# TC37XPD register map
Vendor: Infineon; Series: ATVMC; File version: 100
CPU: other r0p0, little endian, MPU, FPU, vendor SysTick, 4 interrupt priority bits
Registers are 32-bit, read-write, reset 0x0 unless marked. A register's access mark holds for its fields unless they carry their own. Offsets are from the block's base; [hi:lo] are bit positions; lines under a group give offsets from that group; {n}, {i} and the like mark numbered series; 'fields as' and 'values as' point back to an identical list.

## DMU
Base 0xF8040000
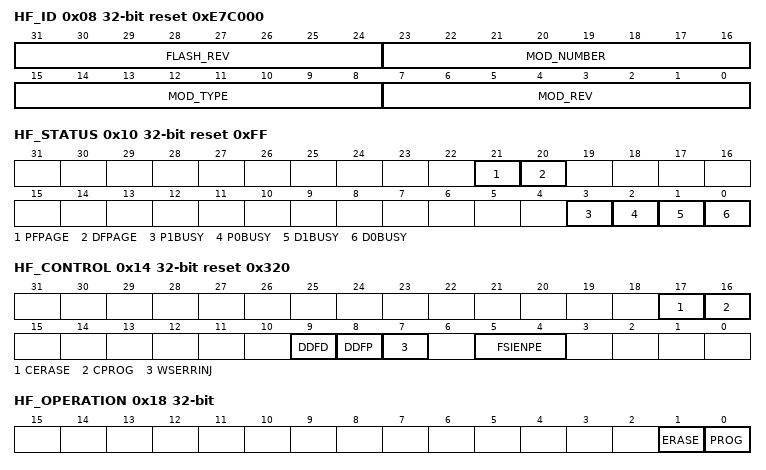
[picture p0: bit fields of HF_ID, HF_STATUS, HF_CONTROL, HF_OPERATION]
0x08 HF_ID ro reset 0xE7C000 (reset mask 0xFFFF00) — Module Identification Register resetvalue={Application Reset:0x0E7C000}
  [31:24] FLASH_REV — Flash Revision FLASH REV. This bit field defines the flash revision number. 31 28 identifies the product. For example 0x9h indicates TC39x product 0x8h indicates TC38x product etc. 27 24 identifies the product revision.
  [23:16] MOD_NUMBER — Module Number Value MOD NUMBER. This bit field defines the module identification number.
  [15:8] MOD_TYPE — Module Type MOD TYPE. The bit field is set to C0 which defines the module as a 32 bit module.
  [7:0] MOD_REV — Module Revision Number MOD REV. This bit field defines the module revision number reflecting major changes in the module.
0x10 HF_STATUS ro reset 0xFF — Flash Status Register resetvalue={Application Reset:0x0FF}
  [21] PFPAGE — Program Flash in Page Mode PFPAGE. HW controlled status flag. Set with Enter Page Mode for Flash cleared with Write Page command This bit is not set by 8220 Enter Page Mode 8221 initiated by the HSM interface. Read accesses are allowed while in page mode.
  [20] DFPAGE — Data Flash in Page Mode DFPAGE. HW controlled status flag. Set with Enter Page Mode for DFLASH cleared with Write Page command. This bit is not set by 8220 Enter Page Mode 8221 initiated by the HSM interface. Read accesses are allowed while in page mode.
  [3] P1BUSY — Program Flash PF5BUSY P5BUSY. HW controlled status flag. Indication of busy state of PFx because of active execution of an operation PFx busy state is also indicated during Flash startup after reset or in sleep mode while in busy state the PFx does not allow read access.
  [2] P0BUSY — Program Flash PF5BUSY P5BUSY. HW controlled status flag. Indication of busy state of PFx because of active execution of an operation PFx busy state is also indicated during Flash startup after reset or in sleep mode while in busy state the PFx does not allow read access.
  [1] D1BUSY — Data Flash Bank 1 Busy D1BUSY. HW controlled status flag. Indication of busy state of DFLASH bank 160 1 because of active execution of an operation DF1 busy state is also indicated during Flash startup after reset or in sleep mode while in busy state the DF1 does not allow read access. Bit is not set for program erase operations initiated by the HSM interface.
  [0] D0BUSY — Data Flash Bank 0 Busy D0BUSY. HW controlled status flag. Indication of busy state of DFLASH bank 160 0 because of active execution of an operation DF0 busy state is also indicated during Flash startup after reset or in sleep mode while in busy state the DF0 does not allow read access.
0x14 HF_CONTROL access per field reset 0x320 — Flash Control Register resetvalue={Application Reset:0x320}
  [17] CERASE wo — Clear Erase State CERASE
  [16] CPROG wo — Clear Programming State CPROG
  [9] DDFD rw — Disable Data Fetch from DF0 EEPROM DDFD. This bit enables disables the data fetch from DF0 EEPROM. DMU ramp up and SSW start up This bit is automatically set with reset and is cleared during startup if no Read Protection installed and during startup BROM SW in case of internal start out of Flash. This is realized by allowing full write access with inactive startup protection. User Software Clearing DF0 EEPROM Read Protection Once set DMU HF CONTROL .DDFD can only be cleared when DMU HF PROTECT .PRODISD or not DMU HF PROCONDF .RPRO User Software Setting DF0 EEPROM Read Protection Software must write DMU HF CONTROL .DDFD to 1
  [8] DDFP rw — Disable Read from PFLASH DDFP. This bit enables disables the read access to PFLASH. DMU ramp up and SSW start up This bit is automatically set with reset and is cleared during startup if no Read Protection installed and during startup SSW in case of internal start out of Flash. This is realized by allowing full write access with inactive startup protection. User Software Clearing PFLASH Read Protection Once set DMU HF CONTROL .DDFP can only be cleared when DMU HF PROTECT .PRODISP or DMU HF PROTECT .PRODISP0 5 or not DMU HF PROCONPF .RPRO User Software Setting PFLASH Read Protection Software must write DMU HF CONTROL .DDFP to 1
  [7] WSERRINJ rw — PFlash Wait State ECC error injection WSERRINJ. Error injection into the ECC logic protecting PFlash Wait states.
  [5:4] FSIENPE rw — Enable Program Erase FSIENPE. The field prevents any Flash program or erase directly in the FSI. It is set to 8220 Enabled 8221 by the SSW upon finishing the startup. Once in the 8220 enabled 8221 state this field cannot be changed.
    0=Disabled0 (00 Disabled Program Erase are disabled in the FSI.); 1=Enabled1 (01 Enabled Program Erase are enabled in the FSI.); 2=Disabled2 (10 Disabled Program Erase are disabled in the FSI.); 3=Disabled3 (11 Disabled Program Erase are disabled in the FSI.)
0x18 HF_OPERATION ro — Flash Operation Register resetvalue={System Reset:0x0}
  [1] ERASE — Erase State ERASE. HW controlled status flag. Set with last cycle of Erase Verify command sequence. Indications are analogous to PROG flag. May be cleared by writing 1 to DMU HF CONTROL .CERASE. This bit is not set for by erase operations initiated by the HSM interface. Cleared with command Clear Status .
  [0] PROG — Programming State PROG. HW controlled status flag. Set with last cycle of Write Page Burst and Replace Logical Sector command sequences. If one BUSY flag is coincidently set PROG indicates the type of busy state. If OPER is coincidently set PROG indicates the type of erroneous operation. Otherwise PROG indicates that operation is still requested or finished. May be also cleared by writing 8216 1 8217 to DMU HF CONTROL .CPROG. This bit is not set for by program operations initiated by the HSM interface. Cleared with command 8220 Clear Status 8221 .
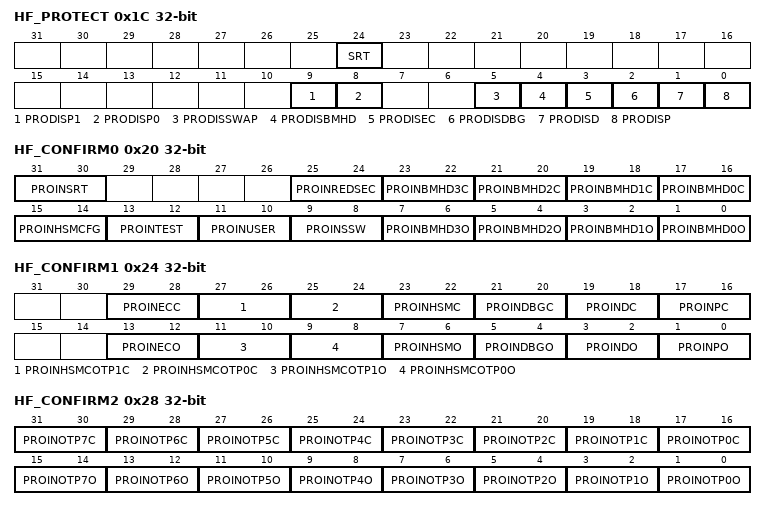
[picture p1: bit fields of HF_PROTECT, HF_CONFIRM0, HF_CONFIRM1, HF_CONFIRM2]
0x1C HF_PROTECT ro — Flash Protection Status Register resetvalue={Application Reset:0x0}
  [24] SRT — Secure Retest Password Protection Disabled SRT. Cleared with command Resume Protection .
  [9] PRODISP1 — Program Flash Protection Disable PRODISP5. The protection configured for PFx by UCB PFLASH ORIG and UCB PFLASH COPY was successfully disabled by supplying the correct password to 8220 Disable Protection 8221 . Cleared with command quot Resume Protection quot .
  [8] PRODISP0 — Program Flash Protection Disable PRODISP5. The protection configured for PFx by UCB PFLASH ORIG and UCB PFLASH COPY was successfully disabled by supplying the correct password to 8220 Disable Protection 8221 . Cleared with command quot Resume Protection quot .
  [5] PRODISSWAP — UCB SWAP protection Disabled PRODISSWAP. The protection configured by UCB SWAP ORIG and UCB SWAP COPY was successfully disabled by supplying the correct password to 8220 Disable Protection 8221 . Cleared with command quot Resume Protection quot .
  [4] PRODISBMHD — BMHD Protection Disabled PRODISBMHD. The protection configured by UCB BMHD0 ORIG and UCB BMHD0 COPY was successfully disabled by supplying the correct password to 8220 Disable Protection 8221 . Cleared with command quot Resume Protection quot .
  [3] PRODISEC — Erase Counter Priority Protection Disabled PRODISEC. The protection configured by UCB ECPRIO ORIG and UCB ECPRIO COPY was successfully disabled by supplying the correct password to 8220 Disable Protection 8221 . Cleared with command quot Resume Protection quot .
  [2] PRODISDBG — Debug Interface Password Protection Disabled PRODISDBG. The password configured by UCB DBG ORIG and UCB DBG COPY was correctly received with 8220 Disable Protection 8221 . When DMU SP PROCONHSMCFG.DESTDBG is 8220 destructive 8221 then only the SSW can disable this protection. This means PRODISDBG is only set when the password matches and DESTDBG 8220 non destructive 8221 or SCU STCON.STP 0 . Cleared with command 8220 Resume Protection 8221 .
  [1] PRODISD — DFLASH Protection Disabled PRODISD. The protection configured by UCB DFLASH ORIG and UCB DFLASH COPY was successfully disabled by supplying the correct password to 8220 Disable Protection 8221 . Cleared with command 8220 Resume Protection 8221 .
  [0] PRODISP — PFLASH Protection Disabled PRODISP. The protection configured by UCB PFLASH ORIG and UCB PFLASH COPY was successfully disabled by supplying the correct password to 8220 Disable Protection 8221 . Cleared with command 8220 Resume Protection 8221 .
0x20 HF_CONFIRM0 ro — Flash Confirm Status Register 0 resetvalue={Application Reset:0x0}
  [31:30] PROINSRT — UCB RETEST Confirmation PROINSRT. This bit reflects the confirmed state of UCB RETEST.
  [25:24] PROINREDSEC — UCB REDSEC Confirmation PROINREDSEC. This bit reflects the confirmed state of UCB REDSEC
  [2n+17:2n+16] PROINBMHD{n}C (n=0..3) — UCB BMHD{n} COPY Confirmation PROINBMHD{n}C. This bit reflects the confirmed state of UCB BMHD{n} COPY.
  [15:14] PROINHSMCFG — UCB HSMCFG Confirmation PROINHSMCFG. This bit reflects the confirmed state of UCB HSMCFG.
  [13:12] PROINTEST — UCB TEST Confirmation PROINTEST. This bit reflects the confirmed state of UCB TEST.
  [11:10] PROINUSER — UCB USER Confirmation PROINUSER. This bit reflects the confirmed state of UCB USER.
  [9:8] PROINSSW — UCB SSW Confirmation PROINSSW. This bit reflects the confirmed state of UCB SSW.
  [2n+1:2n] PROINBMHD{n}O (n=0..3) — UCB BMHD{n} ORIG Confirmation PROINBMHD{n}O. This bit reflects the confirmed state of UCB BMHD{n} ORIG.
0x24 HF_CONFIRM1 ro — Flash Confirm Status Register 1 resetvalue={Application Reset:0x0}
  [29:28] PROINECC — UCB ECPRIO COPY Confirmation PROINECC. This bit reflects the confirmed state of UCB ECPRIO COPY
  [27:26] PROINHSMCOTP1C — UCB HSMCOTP1 COPY Protection PROINHSMCOTP1C. This bit reflects the confirmed state of UCB HSMCOTP1 COPY.
  [25:24] PROINHSMCOTP0C — UCB HSMCOTP0 COPY Protection PROINHSMCOTP0C. This bit reflects the confirmed state of UCB HSMCOTP0 COPY.
  [23:22] PROINHSMC — UCB HSM COPY Confirmation PROINHSMC. This bit reflects the confirmed state of UCB HSM COPY.
  [21:20] PROINDBGC — UCB DBG COPY Interface Confirmation PROINDBGC. This bit reflects the confirmed state of UCB DBG COPY.
  [19:18] PROINDC — UCB DFLASH COPY Confirmation PROINDC. This bit reflects the confirmed state of UCB DFLASH COPY.
  [17:16] PROINPC — UCB PFLASH COPY Confirmation PROINPC. This bit reflects the confirmed state of UCB PFLASH COPY.
  [13:12] PROINECO — UCB ECPRIO ORIG Confirmation PROINECO. This bit reflects the confirmed state of UCB ECPRIO ORIG.
  [11:10] PROINHSMCOTP1O — UCB HSMCOTP1 ORIG Protection PROINHSMCOTP1O. This bit reflects the confirmed state of UCB HSMCOTP1 ORIG.
  [9:8] PROINHSMCOTP0O — UCB HSMCOTP0 ORIG Protection PROINHSMCOTP0O. This bit reflects the confirmed state of UCB HSMCOTP0 ORIG.
  [7:6] PROINHSMO — UCB HSM ORIG Confirmation PROINHSMO. This bit reflects the confirmed state of UCB HSM ORIG.
  [5:4] PROINDBGO — UCB DBG ORIG Confirmation PROINDBGO. This bit reflects the confirmed state of UCB DBG ORIG.
  [3:2] PROINDO — UCB DFLASH ORIG Confirmation PROINDO. This bit reflects the confirmed state of UCB DFLASH ORIG.
  [1:0] PROINPO — UCB PFLASH ORIG Confirmation PROINPO. This bit reflects the confirmed state of UCB PFLASH ORIG.
0x28 HF_CONFIRM2 ro — Flash Confirm Status Register 2 resetvalue={Application Reset:0x0}
  [2n+17:2n+16] PROINOTP{n}C (n=0..7) — UCB OTP{n} COPY Confirmation PROINOTP{n}C. This bit reflects the confirmed state of UCB OTP{n} COPY.
  [2n+1:2n] PROINOTP{n}O (n=0..7) — UCB OTP{n} ORIG Confirmation PROINOTP{n}O. This bit reflects the confirmed state of UCB OTP{n} ORIG.
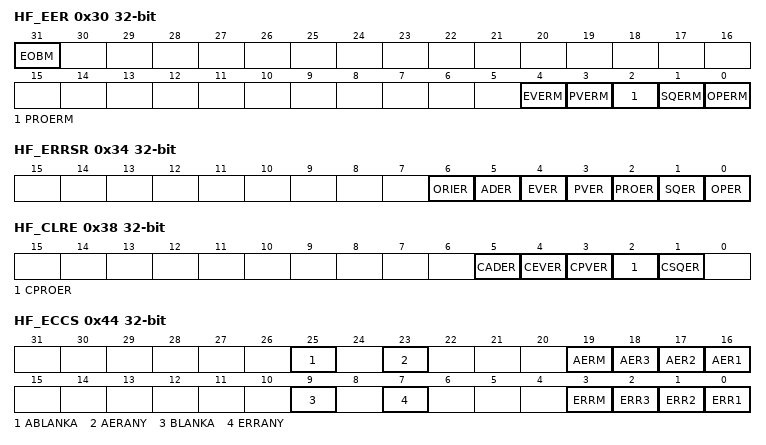
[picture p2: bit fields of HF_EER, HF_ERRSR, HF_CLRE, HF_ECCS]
0x30 HF_EER — Enable Error Interrupt Control Register resetvalue={Application Reset:0x0}
  [31] EOBM — End of Busy Interrupt Mask EOBM
  [4] EVERM — Erase Verify Error Interrupt Mask EVERM
  [3] PVERM — Program Verify Error Interrupt Mask PVERM
  [2] PROERM — Protection Error Interrupt Mask PROERM
  [1] SQERM — Command Sequence Error Interrupt Mask SQERM
  [0] OPERM — Operation Error Interrupt Mask OPERM
0x34 HF_ERRSR ro — Error Status Register resetvalue={Application Reset:0x0}
  [6] ORIER — Original Error ORIER. If a UCB contains both ORIG and COPY confirmation codes and during startup an ERRORED value or an uncorrectable ECC error is detected in the ORIG confirmation code then the original error flag is set by hardware. Cleared with application reset.
  [5] ADER — SRI Bus Address ECC Error ADER. This flag is set when the DMU detects an ECC error in the address phase bus transaction on the SRI bus. Cleared with application reset or writing DMU HF CLRE .CADER 1 .
  [4] EVER — Erase Verify Error EVER. A verify error was reported on completion of a Flash erase operation even when the operation was directly started in the FSI . Cleared with application reset with the command Clear Status or writing DMU HF CLRE .CEVER 1 .
  [3] PVER — Program Verify Error PVER. A verify error was reported on completion of a Flash program operation even when the operation was directly started in the FSI Cleared with application reset with the command 8220 Clear Status 8221 or writing DMU HF CLRE .CPVER 1 .
  [2] PROER — Protection Error PROER. A Protection Error is reported e.g. because of a not allowed command for example an Erase or Write Page command addressing a locked sector or because of wrong password s in a protected command sequence such as Disable Read Protection . A Protection Error is also reported if the safety protection prevented a program erase operation in Flash. Cleared with application reset with the command Clear Status or writing DMU HF CLRE .CPROER 1 .
  [1] SQER — Command Sequence Error SQER. A sequence error is not indicated if the Reset to Read command aborts a command sequence. Cleared with application reset commands Reset to Read and Clear Status or writing DMU HF CLRE .CSQER 1 .
  [0] OPER — Flash Operation Error OPER. Cleared with system reset.
0x38 HF_CLRE wo — Clear Error Register resetvalue={Application Reset:0x0}
  [5] CADER — Clear SRI Bus Address ECC Error CADER
  [4] CEVER — Clear Erase Verify Error CEVER
  [3] CPVER — Clear Program Verify Error CPVER
  [2] CPROER — Clear Protection Error CPROER
  [1] CSQER — Clear Command Sequence Error CSQER
0x40 HF_ECCR ro — DF0 ECC Read Register resetvalue={Application Reset:0x0}
  [21:0] RCODE — Error Correction Read Code RCODE. ECC checksum read during the last NVM read access.
0x44 HF_ECCS ro — DF0 ECC Status Register resetvalue={Application Reset:0x0}
  [25] ABLANKA — Accumulated Blank Analog ABLANKA. The flag accumulates analog evaluated blank failures during NVM read accesses. It reports that all read data cells have sufficient high current a program of new data without prior erase is possible. Under certain operation history a valid complement data entry may also appear as blank. Data qualifiers like headers or footers which are usually used in EEPROM emulation can be used to distinguish expected valid data from unknown data fields. Only blank failures in Complement Sensing mode are reported in this flag and is intended for use only in this mode. Blank failures in Single Ended mode is also reported when in CFTM. Reset by hardware when DMU HF ECCC .CLR is written to 11 .
  [23] AERANY — Accumulated Any Read Access ECC Error AERANY. The status bit accumulates ECC failures during NVM read accesses. Reset by hardware when DMU HF ECCC .CLR is written to 11 .
  [19] AERM — Accumulated Multi bit ECC Errors AERM. The status bit accumulates multi bit failures during NVM read accesses. Reset by hardware when DMU HF ECCC .CLR is written to 11 .
  [18] AER3 — Accumulated Triple Bit ECC Errors AER3. The status flag accumulates triple bit failures during NVM read operations. Reset by hardware when DMU HF ECCC .CLR is written to 11 .
  [17] AER2 — Accumulated Double Bit ECC Errors AER2. The status flag accumulates double bit failures during NVM read operations. Reset by hardware when DMU HF ECCC .CLR is written to 11 .
  [16] AER1 — Accumulated Single Bit ECC Errors AER1. The status flag accumulates single bit failures during NVM read operations. Reset by hardware when DMU HF ECCC .CLR is written to 11 .
  [9] BLANKA — Read Access Blank Analog BLANKA. The flag reports that all read data cells have sufficient high current a program of new data without prior erase is possible. Under certain operation history a valid complement data entry may also appear as blank. Data qualifiers like headers or footers which are usually used in EEPROM emulation can be used to distinguish expected valid data from unknown data fields. Only blank failures in Complement Sensing mode are reported in this flag and is intended for use only in this mode. Blank failures in Single Ended mode are also reported when in CFTM. Reset by hardware when DMU HF ECCC .CLR is written to 11 .
  [7] ERRANY — Any Read Access ECC Error ERRANY. The flag reports any ECC failure during the last NVM read access. Reset by hardware when DMU HF ECCC .CLR is written to 11 .
  [3] ERRM — Read Access Multi bit ECC Error ERRM. The flag reports multi bit ECC failure during the last NVM read access. Reset by hardware when DMU HF ECCC .CLR is written to 11 .
  [2] ERR3 — Read Access Triple Bit ECC Error ERR3. The flag reports a triple bit ECC failure during the last NVM read access. Reset by hardware when DMU HF ECCC .CLR is written to 11 .
  [1] ERR2 — Read Access Double Bit ECC Error ERR2. The flag reports a double bit ECC failure during the last NVM read access. Reset by hardware when DMU HF ECCC .CLR is written to 11 .
  [0] ERR1 — Read Access Single Bit ECC Error ERR1. The flag reports a single bit ECC failure during the last NVM read access. Reset by hardware when DMU HF ECCC .CLR is written to 11 .
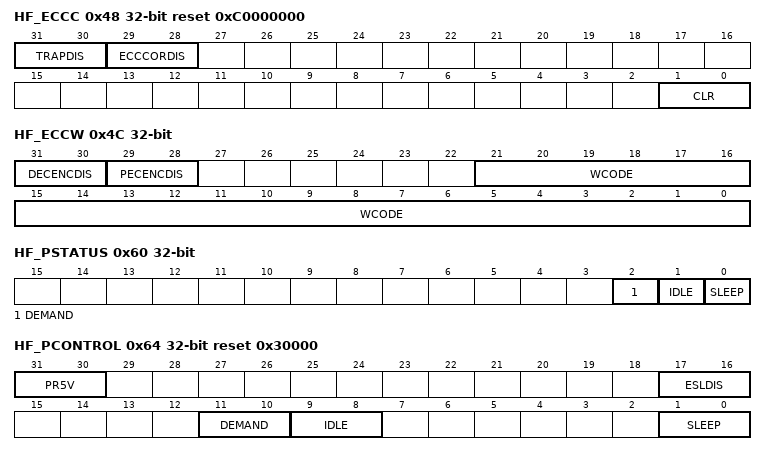
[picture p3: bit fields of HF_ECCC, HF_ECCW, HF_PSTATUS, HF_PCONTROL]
0x48 HF_ECCC access per field reset 0xC0000000 — DF0 ECC Control Register resetvalue={Application Reset:0x0C0000000}
  [31:30] TRAPDIS rw — Host Command Interface Uncorrectable ECC Bit Error Trap Disable TRAPDIS. Includes CFS and UCB uncorrectable errors.
  [29:28] ECCCORDIS rw — Host Command Interface ECC Correction Disable ECCCORDIS
    0=Enabled0 (00 Enabled ECC correction is enabled for the DF0 read path and if DF1 is configured as not HSM exclusive then for the DF1 read path.); 1=Enabled1 (01 Enabled ECC correction is enabled for the DF0 read path and if DF1 is configured as not HSM exclusive then for the DF1 read path.); 2=Enabled2 (10 Enabled ECC correction is enabled for the DF0 read path and if DF1 is configured as not HSM exclusive then for the DF1 read path.); 3=Disabled3 (11 Disabled ECC correction is disabled for the DF0 read path and if DF1 is configured as not HSM exclusive then for the DF1 read path.)
  [1:0] CLR wo — Clear ECC status bits CLR
0x4C HF_ECCW — DF0 ECC Write Register resetvalue={Application Reset:0x0}
  [31:30] DECENCDIS — DFLASH ECC Encoding Disable DECENCDIS
  [29:28] PECENCDIS — PFLASH ECC Encoding Disable PECENCDIS
  [21:0] WCODE — Error Correction Write Code WCODE. 22 bit ECC code for the current 64 bit for DFLASH or 256 bit for PFLASH write buffer to be written into the assembly buffer instead of a generated ECC.
0x50 HF_CCONTROL — Cranking Control Register resetvalue={System Reset:0x0}
  [1:0] CRANKING — Cranking Mode Control CRANKING. This bit field determins Cranking mode.
0x60 HF_PSTATUS ro — Power Status Register resetvalue={Application Reset:0x0}
  [2] DEMAND — Demand DEMAND. For Cranking Mode DMU HF PSTATUS .DEMAND 1
  [1] IDLE — Dynamic Idle IDLE
  [0] SLEEP — Sleep Mode SLEEP
0x64 HF_PCONTROL access per field reset 0x30000 — Power Control Register resetvalue={Application Reset:0x30000}
  [31:30] PR5V rw — Programming Supply 5V PR5V. Selects the supply for programming.
    0=P3V0 (00 P3V The programming voltage is internally generated.); 1=P3V1 (01 P3V The programming voltage is internally generated.); 2=P3V2 (10 P3V The programming voltage is internally generated.); 3=P5V3 (11 P5V As programming voltage the external 5 V supply is used.)
  [17:16] ESLDIS rw — External Sleep Mode Request Disable ESLDIS. Used for Sleep Mode control. The Sleep Mode request is generated by the SCU.
  [11:10] DEMAND wo — Demand Enable DEMAND
  [9:8] IDLE wo — Dynamic Idle Enable IDLE
  [1:0] SLEEP rw — Sleep Mode Control SLEEP. This bit field determines the Sleep mode.
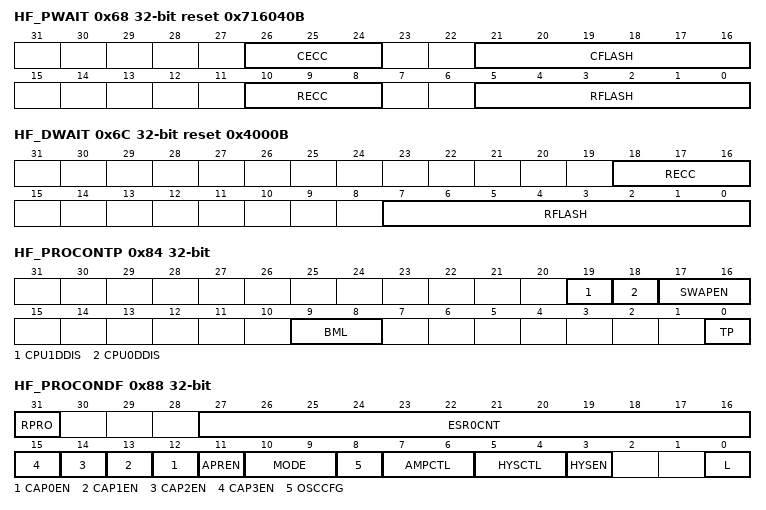
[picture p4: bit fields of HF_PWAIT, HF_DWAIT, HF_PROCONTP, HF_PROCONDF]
0x68 HF_PWAIT reset 0x716040B — PFLASH Wait Cycle Register resetvalue={System Reset:0x716040B}
  [26:24] CECC — Cranking Mode CECC. PFLASH Error Correction Cycles This bit field defines the number of SRI clock cycles for the PFLASH Bank ECC correction.
  [21:16] CFLASH — Cranking Mode CFLASH. PFLASH Wait Cycles This bit field defines the number of SRI clock cycles for a PFLASH Bank read access.
  [10:8] RECC — Operation Mode RECC. PFLASH Error Correction Cycles This bit field defines the number of SRI clock cycles for the PFLASH Bank ECC correction.
  [5:0] RFLASH — Operation Mode RFLASH. PFLASH Wait Cycles This bit field defines the number of SRI clock cycles for a PFLASH Bank read access.
0x6C HF_DWAIT reset 0x4000B — DFLASH Wait Cycle Register resetvalue={System Reset:0x4000B}
  [18:16] RECC — Operation Mode RECC. DFLASH Error Correction Cycles This bit field defines the number of FSI clock cycles for the DFLASH Bank ECC correction.
  [7:0] RFLASH — Operation Mode RFLASH. DFLASH Wait Cycles for Flash This bit field defines the number of FSI clock cycles for a DFLASH Bank read access.
0x74 HF_PROCONUSR ro — DF0 User Mode Control resetvalue={Application Reset:0x0,CFS Value:0x0}
  [1:0] MODE — DF0 User Mode Control MODE. Configures the DF0 mode when the user has control.
0x80 HF_PROCONPF ro — PFLASH Protection Configuration resetvalue={Application Reset:0x0,CFS Value:0x0}
  [31] RPRO — Read Protection Configuration RPRO. This bit indicates whether read protection is configured for PFLASH sectors.
0x84 HF_PROCONTP ro — Tuning Protection Configuration resetvalue={Application Reset:0x0,CFS Value:0x0}
  [19] CPU1DDIS — Disable direct LPB access. Disable direct LPB access by the CPU to the Local PFlash Bank LPB .
  [18] CPU0DDIS — Disable direct LPB access. Disable direct LPB access by the CPU to the Local PFlash Bank LPB .
  [17:16] SWAPEN — Enable SOTA mode SWAPEN. This field enables the entry into Software update Over the Air SOTA mode . In this mode an alternate PFLASH address map can be selected. Please refer to the SOTA section of the Introduction chapter for more details.
    0=Disabled0 (00 Disabled SOTA mode disabled.); 1=Disabled1 (01 Disabled SOTA mode disabled.); 2=Disabled2 (10 Disabled SOTA mode disabled.); 3=Enabled3 (11 Enabled SOTA mode enabled.)
  [9:8] BML — Boot Mode Lock BML. Used by the SSW to restrict the boot mode selection.
  [0] TP — Tuning Protection TP. This bit indicates whether tuning protection is installed or not.
0x88 HF_PROCONDF ro — DFLASH Protection Configuration resetvalue={Application Reset:0x0,CFS Value:0x0}
  [31] RPRO — Read Protection Configuration RPRO. This bit indicates whether read protection is configured for DFLASH sectors.
  [27:16] ESR0CNT — ESR0 Prolongation Counter ESR0CNT. Used to configure the ESR0 delay. Evaluation by SSW.
  [n+12] CAP{n}EN (n=0..3) — OSC Capacitance 3 Enable x 0 3 CAP3EN. When enabled by OSCCFG these fields are copied to SCU OSCCON.CAPxEN.
  [11] APREN — OSC Amplitude Regulation Enable APREN. When enabled by OSCCFG this field is copied to SCU OSCCON.APREN.
  [10:9] MODE — OSC Mode MODE. When enabled by OSCCFG this field is copied to SCU OSCCON.MODE.
  [8] OSCCFG — OSC Configuration by SSW OSCCFG. This bit indicates whether the oscillator configuration fields CAPxEN APREN MODE HYSEN HYSCTL AMPCTL are installed by the SSW in SCU OSCCON.
  [7:6] AMPCTL — Amplitude Control. When enabled by OSCCFG these fields are copied to SCU OSCCON.AMPCTL
  [5:4] HYSCTL — Hysteresis Control. When enabled by OSCCFG these fields are copied to SCU OSCCON.HYSCTL
  [3] HYSEN — Hysteresis enable. When enabled by OSCCFG these fields are copied to SCU OSCCON.HYSEN
  [0] L — DF0 EEPROM Locked for Write Protection L. This bit indicates whether the DFLASH sectors EEPROMx are write protected.
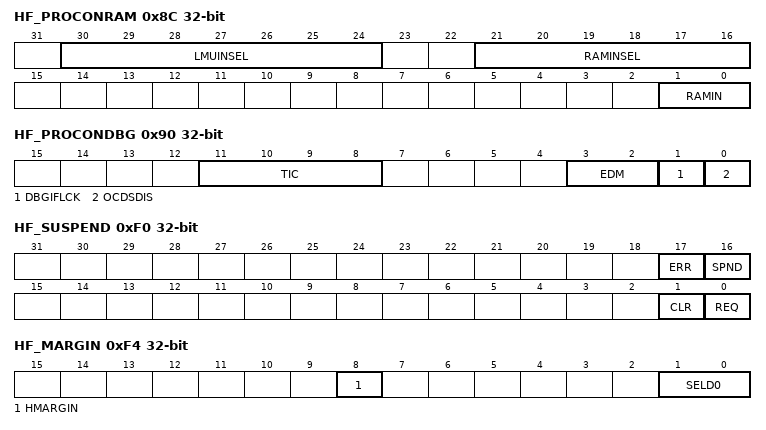
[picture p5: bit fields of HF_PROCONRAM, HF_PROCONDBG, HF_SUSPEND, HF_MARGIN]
0x8C HF_PROCONRAM ro — RAM Configuration resetvalue={Application Reset:0x0,CFS Value:0x0}
  [30:24] LMUINSEL — LMU Initialization Selection LMUINSEL. These bits select which memories are initialized when the RAM initialization is configured with RAMIN. See CROSSREFERENCE .
  [21:16] RAMINSEL — RAM Initialization Selection RAMINSEL. These bits select which memories are initialized when the RAM initialization is configured with RAMIN. See CROSSREFERENCE .
  [1:0] RAMIN — RAM Initialization by SSW Control RAMIN. These bits defined whether the RAMs selected by the field RAMINSEL are initialized. This field determines also if a RAM is initialized before MBIST access is granted. In all Init cases a RAM is initialized before MBIST access is enabled in the No Init case a RAM is not erased. This is independent of the memory selection with RAMINSEL for initialization during startup see MTU chapter .
    0=Init_All0 (00 Init All RAM initialization is performed after cold power on reset and warm power on reset.); 1=Init_Warm1 (01 Init Warm RAM initialization is performed after warm power on resets but not after cold power on reset not recommended .); 2=Init_Cold2 (10 Init Cold RAM initialization is performed after cold power on reset.); 3=No_Init3 (11 No Init No RAM initialization is performed.)
0x90 HF_PROCONDBG ro (reset mask 0xFFFFFEFF) — Debug Interface Protection Configuration resetvalue={Application Reset:0x100,CFS Value:0x0}
  [11:8] TIC — Tool Interface Control TIC. DAP over CAN Physical Layer DXCPL . Others Reserved.
  [3:2] EDM — Entered Debug Mode EDM. This bit indicates whether the debug interface has been opened via Destructive Debug Entry. Consequently the CAN and FlexRay operation is made impossible
  [1] DBGIFLCK — Debug Interface Locked DBGIFLCK. This bit indicates whether the debug interface is configured as locked.
  [0] OCDSDIS — OCDS Disabled OCDSDIS. This bit indicates whether the OCDS is configured as locked.
0xF0 HF_SUSPEND access per field — Suspend Control Register resetvalue={Application Reset:0x0}
  [17] ERR ro — Suspend Error ERR. Reset by hardware when DMU HF SUSPEND .CLR is written to 1 .
  [16] SPND ro — Flash Operation Suspended SPND. Suspension of a Flash program or erase operation.
  [1] CLR wo — Suspend Clear CLR. Software write only active high clear of Suspend Error.
  [0] REQ rw — Suspend Request REQ
0xF4 HF_MARGIN — Margin Control Register resetvalue={Application Reset:0x0}
  [8] HMARGIN — Hard Margin Selection HMARGIN. Suboptimal 0 bits are read as 1s. Suboptimal 1 bits are read as 0s. The concrete margin values are restored from the configuration sector and are determined by Infineon.
    0=Tight00 (0 Tight0 Tight margin for 0 low level.); 1=Tight11 (1 Tight1 Tight margin for 1 high level.)
  [1:0] SELD0 — DF0 Margin Read Selection SELD0. If a change between the standard and hard read margin setting is done the system must wait a delay time t FL MarginDel until the next read is requested.
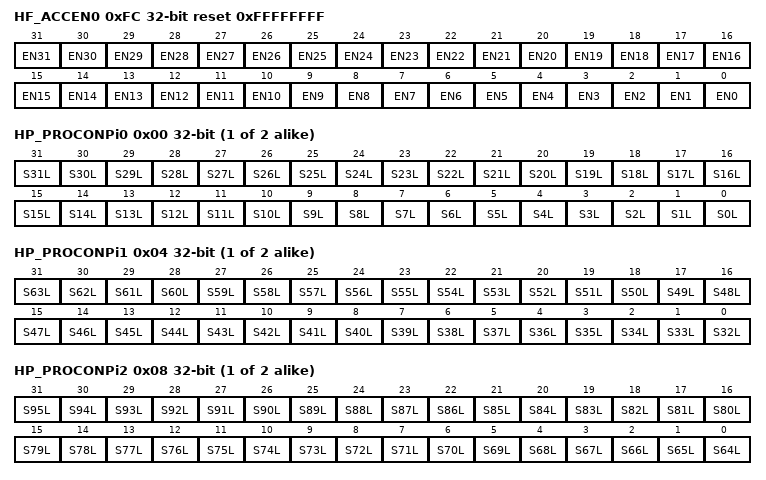
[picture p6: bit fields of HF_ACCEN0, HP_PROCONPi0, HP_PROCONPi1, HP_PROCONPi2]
0xFC HF_ACCEN0 reset 0xFFFFFFFF — Access Enable Register 0 resetvalue={Application Reset:0x0FFFFFFFF}
  [31] EN31 — Access Enable for Master TAG ID 31 EN31. This bit enables read write access to the module kernel addresses for transactions with the Master TAG ID 30
  [30] EN30 — Access Enable for Master TAG ID 30 EN30. This bit enables write access to the module kernel addresses for transactions with the Master TAG ID 30
  [29] EN29 — Access Enable for Master TAG ID 29 EN29. This bit enables read write access to the module kernel addresses for transactions with the Master TAG ID 29
  [28] EN28 — Access Enable for Master TAG ID 28 EN28. This bit enables write access to the module kernel addresses for transactions with the Master TAG ID 28
  [n] EN{n} (n=4..27) — Access Enable for Master TAG ID 27 EN27. This bit enables read write access to the module kernel addresses for transactions with the Master TAG ID y
  [3] EN3 — Access Enable for Master TAG ID 3 EN3. This bit enables write access to the module kernel addresses for transactions with the Master TAG ID 3
  [2] EN2 — Access Enable for Master TAG ID 2 EN2. This bit enables read write access to the module kernel addresses for transactions with the Master TAG ID y
  [1] EN1 — Access Enable for Master TAG ID 2 EN2. This bit enables read write access to the module kernel addresses for transactions with the Master TAG ID y
  [0] EN0 — Access Enable for Master TAG ID 2 EN2. This bit enables read write access to the module kernel addresses for transactions with the Master TAG ID y
{0x10000+0x100*i} HP[{i}] (i=0..1) group
  0x00 HP_PROCONPi0 ro — PFLASH Bank 0 Protection Configuration 0 resetvalue={Application Reset:0x0,CFS Value:0x0}
    [n] S{n}L (n=0..31) — PFLASH p Sector 31 Locked for Write Protection S31L. These bits indicate whether PFLASH sector x is write protected.
  0x04 HP_PROCONPi1 ro — PFLASH Bank 0 Protection Configuration 1 resetvalue={Application Reset:0x0,CFS Value:0x0}
    [n-32] S{n}L (n=32..63) — PFLASH p Sector 63 Locked for Write Protection S63L. These bits indicate whether PFLASH sector x is write protected.
  0x08 HP_PROCONPi2 ro — PFLASH Bank 0 Protection Configuration 2 resetvalue={Application Reset:0x0,CFS Value:0x0}
    [n-64] S{n}L (n=64..95) — PFLASH p Sector 95 Locked for Write Protection S95L. These bits indicate whether PFLASH sector x is write protected.
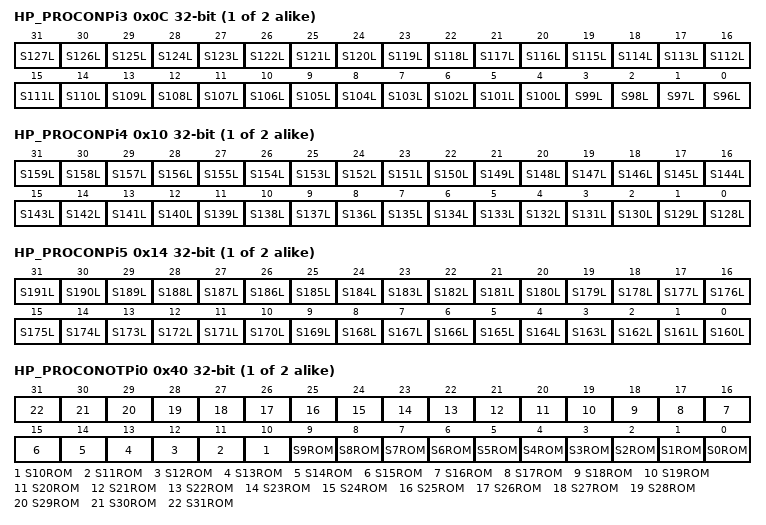
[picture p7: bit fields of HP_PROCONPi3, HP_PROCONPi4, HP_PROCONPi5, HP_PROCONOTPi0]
  0x0C HP_PROCONPi3 ro — PFLASH Bank 0 Protection Configuration 3 resetvalue={Application Reset:0x0,CFS Value:0x0}
    [n-96] S{n}L (n=96..127) — PFLASH p Sector 127 Locked for Write Protection S127L. These bits indicate whether PFLASH sector x is write protected.
  0x10 HP_PROCONPi4 ro — PFLASH Bank 0 Protection Configuration 4 resetvalue={Application Reset:0x0,CFS Value:0x0}
    [n-128] S{n}L (n=128..159) — PFLASH p Sector 159 Locked for Write Protection S159L. These bits indicate whether PFLASH sector x is write protected.
  0x14 HP_PROCONPi5 ro — PFLASH Bank 0 Protection Configuration 5 resetvalue={Application Reset:0x0,CFS Value:0x0}
    [n-160] S{n}L (n=160..191) — PFLASH p Sector 191 Locked for Write Protection S191L. These bits indicate whether PFLASH sector x is write protected.
  0x40 HP_PROCONOTPi0 ro — PFLASH Bank 0 OTP Protection Configuration 0 resetvalue={Application Reset:0x0,CFS Value:0x0}
    [n] S{n}ROM (n=0..31) — PFLASH p Sector 31 Locked for Forever S31ROM. These bits indicate whether PFLASH p sector x is an OTP protected sector with read only functionality.
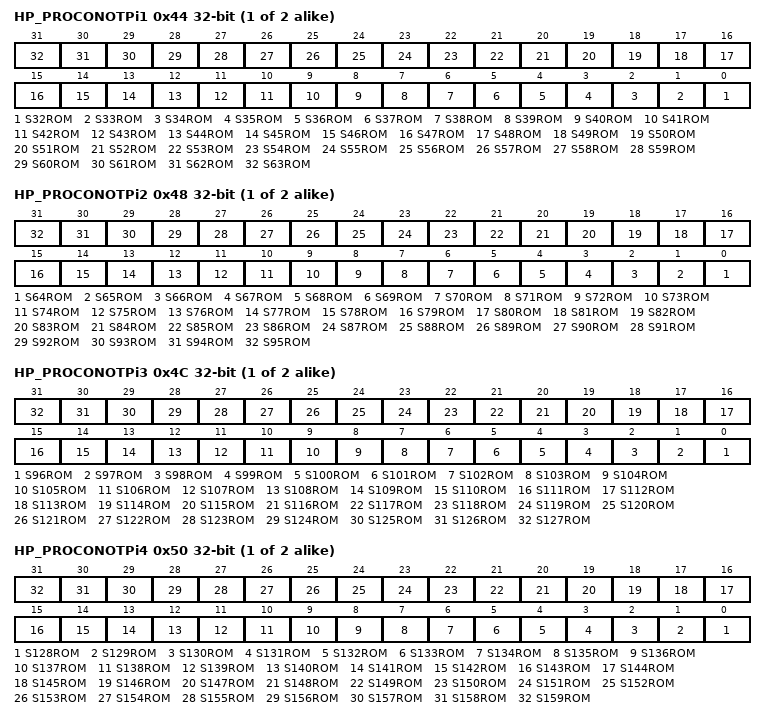
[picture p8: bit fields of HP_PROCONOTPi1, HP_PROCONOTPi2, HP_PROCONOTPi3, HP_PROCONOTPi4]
  0x44 HP_PROCONOTPi1 ro — PFLASH Bank 0 OTP Protection Configuration 1 resetvalue={Application Reset:0x0,CFS Value:0x0}
    [n-32] S{n}ROM (n=32..63) — PFLASH p Sector 63 Locked for Forever S63ROM. These bits indicate whether PFLASH p sector x is an OTP protected sector with read only functionality.
  0x48 HP_PROCONOTPi2 ro — PFLASH Bank 0 OTP Protection Configuration 2 resetvalue={Application Reset:0x0,CFS Value:0x0}
    [n-64] S{n}ROM (n=64..95) — PFLASH p Sector 95 Locked for Forever S95ROM. These bits indicate whether PFLASH p sector x is an OTP protected sector with read only functionality.
  0x4C HP_PROCONOTPi3 ro — PFLASH Bank 0 OTP Protection Configuration 3 resetvalue={Application Reset:0x0,CFS Value:0x0}
    [n-96] S{n}ROM (n=96..127) — PFLASH p Sector 127 Locked for Forever S127ROM. These bits indicate whether PFLASH p sector x is an OTP protected sector with read only functionality.
  0x50 HP_PROCONOTPi4 ro — PFLASH Bank 0 OTP Protection Configuration 4 resetvalue={Application Reset:0x0,CFS Value:0x0}
    [n-128] S{n}ROM (n=128..159) — PFLASH p Sector 159 Locked for Forever S159ROM. These bits indicate whether PFLASH p sector x is an OTP protected sector with read only functionality.
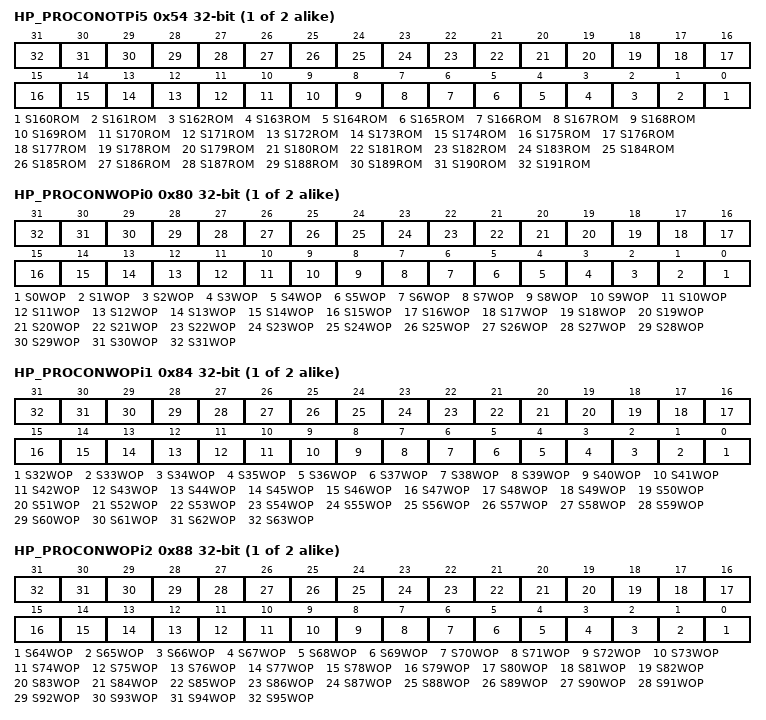
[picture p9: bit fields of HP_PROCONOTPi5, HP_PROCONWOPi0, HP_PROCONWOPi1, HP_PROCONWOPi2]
  0x54 HP_PROCONOTPi5 ro — PFLASH Bank 0 OTP Protection Configuration 5 resetvalue={Application Reset:0x0,CFS Value:0x0}
    [n-160] S{n}ROM (n=160..191) — PFLASH p Sector 191 Locked for Forever S191ROM. These bits indicate whether PFLASH p sector x is an OTP protected sector with read only functionality.
  0x80 HP_PROCONWOPi0 ro — PFLASH Bank 0 WOP Configuration 0 resetvalue={Application Reset:0x0,CFS Value:0x0}
    [n] S{n}WOP (n=0..31) — PFLASH p Sector 31 Configured for Write Once Protection S31WOP. These bits indicate whether PFLASH p sector x is an WOP protected sector.
  0x84 HP_PROCONWOPi1 ro — PFLASH Bank 0 WOP Configuration 1 resetvalue={Application Reset:0x0,CFS Value:0x0}
    [n-32] S{n}WOP (n=32..63) — PFLASH p Sector 63 Configured for Write Once Protection S63WOP. These bits indicate whether PFLASH p sector x is an WOP protected sector.
  0x88 HP_PROCONWOPi2 ro — PFLASH Bank 0 WOP Configuration 2 resetvalue={Application Reset:0x0,CFS Value:0x0}
    [n-64] S{n}WOP (n=64..95) — PFLASH p Sector 95 Configured for Write Once Protection S95WOP. These bits indicate whether PFLASH p sector x is an WOP protected sector.
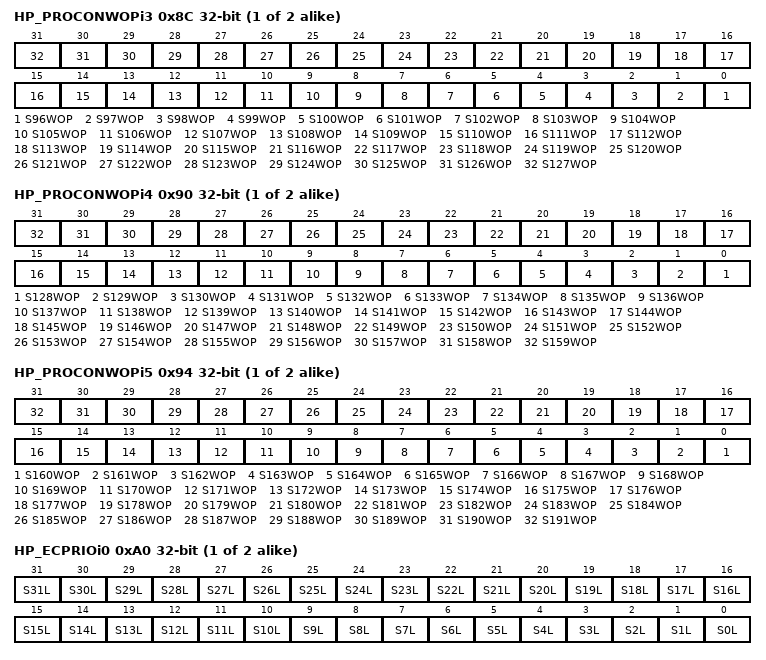
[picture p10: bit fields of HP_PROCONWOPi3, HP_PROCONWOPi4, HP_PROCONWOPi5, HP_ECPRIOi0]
  0x8C HP_PROCONWOPi3 ro — PFLASH Bank 0 WOP Configuration 3 resetvalue={Application Reset:0x0,CFS Value:0x0}
    [n-96] S{n}WOP (n=96..127) — PFLASH p Sector 127 Configured for Write Once Protection S127WOP. These bits indicate whether PFLASH p sector x is an WOP protected sector.
  0x90 HP_PROCONWOPi4 ro — PFLASH Bank 0 WOP Configuration 4 resetvalue={Application Reset:0x0,CFS Value:0x0}
    [n-128] S{n}WOP (n=128..159) — PFLASH p Sector 159 Configured for Write Once Protection S159WOP. These bits indicate whether PFLASH p sector x is an WOP protected sector.
  0x94 HP_PROCONWOPi5 ro — PFLASH Bank 0 WOP Configuration 5 resetvalue={Application Reset:0x0,CFS Value:0x0}
    [n-160] S{n}WOP (n=160..191) — PFLASH p Sector 191 Configured for Write Once Protection S191WOP. These bits indicate whether PFLASH p sector x is an WOP protected sector.
  0xA0 HP_ECPRIOi0 ro — PFLASH Bank 0 Erase Counter Priority configuration 0 resetvalue={Application Reset:0x0,CFS Value:0x0}
    [n] S{n}L (n=0..31) — PFLASH p Sector 31 Erase Counter priority S31L. These bits indicate whether PFLASH sector x has high or low priority for Erase Counter recording.
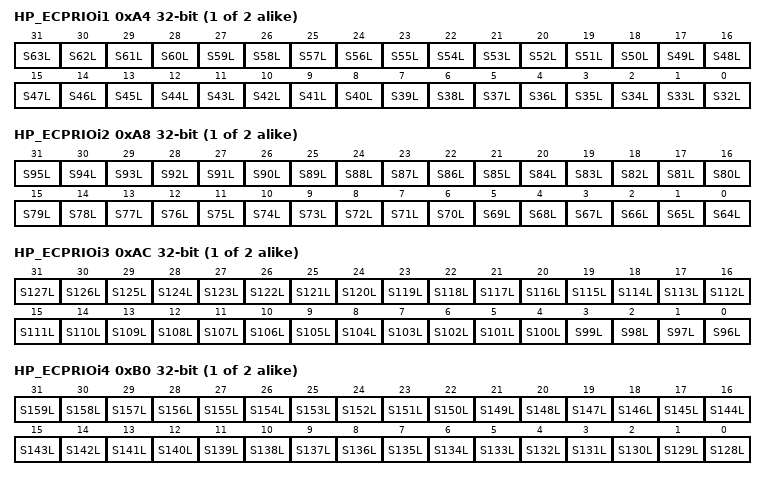
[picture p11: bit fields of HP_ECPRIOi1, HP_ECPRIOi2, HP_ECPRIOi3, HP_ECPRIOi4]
  0xA4 HP_ECPRIOi1 ro — PFLASH Bank 0 Erase Counter Priority Configuration 1 resetvalue={Application Reset:0x0,CFS Value:0x0}
    [n-32] S{n}L (n=32..63) — PFLASH p Sector 63 Erase Counter priority S63L. These bits indicate whether PFLASH sector x has high or low priority for Erase Counter recording.
  0xA8 HP_ECPRIOi2 ro — PFLASH Bank 0 Erase Counter Priority Configuration 2 resetvalue={Application Reset:0x0,CFS Value:0x0}
    [n-64] S{n}L (n=64..95) — PFLASH p Sector 95 Erase Counter priority S95L. These bits indicate whether PFLASH sector x has high or low priority for Erase Counter recording.
  0xAC HP_ECPRIOi3 ro — PFLASH Bank 0 Erase Counter Priority Configuration 3 resetvalue={Application Reset:0x0,CFS Value:0x0}
    [n-96] S{n}L (n=96..127) — PFLASH p Sector 127 Erase Counter priority S127L. These bits indicate whether PFLASH sector x has high or low priority for Erase Counter recording.
  0xB0 HP_ECPRIOi4 ro — PFLASH Bank 0 Erase Counter Priority Configuration 4 resetvalue={Application Reset:0x0,CFS Value:0x0}
    [n-128] S{n}L (n=128..159) — PFLASH p Sector 159 Erase Counter priority S159L. These bits indicate whether PFLASH sector x has high or low priority for Erase Counter recording.
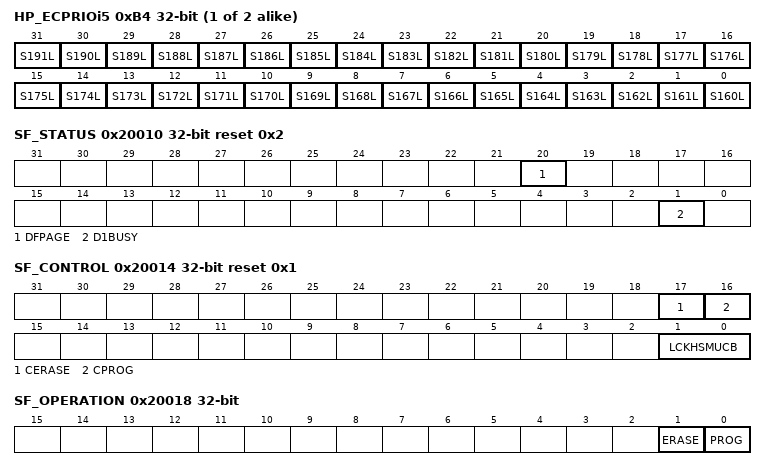
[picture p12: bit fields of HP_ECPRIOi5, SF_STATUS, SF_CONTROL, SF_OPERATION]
  0xB4 HP_ECPRIOi5 ro — PFLASH Bank 0 Erase Counter Priority Configuration 5 resetvalue={Application Reset:0x0,CFS Value:0x0}
    [n-160] S{n}L (n=160..191) — PFLASH p Sector 191 Erase Counter priority S191L. These bits indicate whether PFLASH sector x has high or low priority for Erase Counter recording.
0x20010 SF_STATUS ro reset 0x2 — HSM Flash Status Register resetvalue={Application Reset:0x2}
  [20] DFPAGE — Data Flash in Page Mode DFPAGE. HW controlled status flag. Set with Enter Page Mode for DFLASH cleared with Write Page command. Read accesses are allowed while in page mode.
  [1] D1BUSY — Data Flash Bank 1 Busy D1BUSY. HW controlled status flag. Indication of busy state of DFLASH bank 1 because of active execution of an operation DF1 busy state is also indicated during Flash startup after reset or in sleep mode while in busy state the DF1 does not allow read access.
0x20014 SF_CONTROL access per field reset 0x1 — HSM Flash Configuration Register resetvalue={Application Reset:0x1}
  [17] CERASE wo — Clear Erase State CERASE
  [16] CPROG wo — Clear Programming State CPROG
  [1:0] LCKHSMUCB rw — Lock Access to UCB HSMCFG LCKHSMUCB. Trap door register. This field can only be written to the x201c Locked x201d state. Other writes are ignored.
    0=Locked0 (00 Locked Reads to UCB HSMCFG forbidden.); 1=Unlocked1 (01 Unlocked Reads by HSM to UCB HSMCFG allowed.); 2=Locked2 (10 Locked Reads to UCB HSMCFG forbidden.); 3=Locked3 (11 Locked Reads to UCB HSMCFG forbidden.)
0x20018 SF_OPERATION ro — HSM Flash Operation Register resetvalue={System Reset:0x0}
  [1] ERASE — Erase State ERASE. HW controlled status flag. Set with last cycle of Erase Verify command sequence. Indications are analogous to PROG flag. Can be also cleared by writing 8216 11 8217 to DMU SF CONTROL .CERASE. This bit is not set for by erase operations initiated by the Host interface. Cleared with command 8220 Clear Status 8221 .
  [0] PROG — Programming State PROG. HW controlled status flag. Set with last cycle of Write Page Burst command sequence. If one BUSY flag is coincidently set PROG indicates the type of busy state. If OPER is coincidently set PROG indicates the type of erroneous operation. Otherwise PROG indicates that operation is still requested or finished. Can be also cleared by writing 8216 11 8217 to DMU SF CONTROL .CPROG. This bit is not set for by program operations initiated by the Host interface. Cleared with command 8220 Clear Status 8221 .
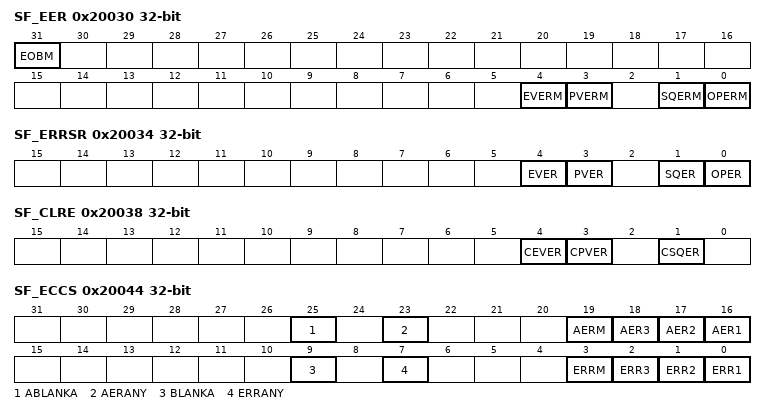
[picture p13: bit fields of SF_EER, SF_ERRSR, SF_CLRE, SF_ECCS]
0x20030 SF_EER — HSM Enable Error Interrupt Control Register resetvalue={Application Reset:0x0}
  [31] EOBM — End of Busy Interrupt Mask EOBM
  [4] EVERM — Erase Verify Error Interrupt Mask EVERM
  [3] PVERM — Program Verify Error Interrupt Mask PVERM
  [1] SQERM — Command Sequence Error Interrupt Mask SQERM
  [0] OPERM — Operation Error Interrupt Mask OPERM
0x20034 SF_ERRSR ro — HSM Error Status Register resetvalue={Application Reset:0x0}
  [4] EVER — Erase Verify Error EVER. A verify error was reported on completion of a Flash erase operation even when the operation was directly started in the FSI . Cleared with application reset with the command Clear Status or writing DMU SF CLRE .CEVER 1 .
  [3] PVER — Program Verify Error PVER. A verify error was reported on completion of a Flash program operation even when the operation was directly started in the FSI . Cleared with application reset with the command Clear Status or writing DMU SF CLRE .CPVER 1 .
  [1] SQER — Command Sequence Error SQER. A sequence error is not indicated if the Reset to Read command aborts a command sequence. Cleared with application reset commands Reset to Read and Clear Status or writing DMU SF CLRE .CSQER 1 .
  [0] OPER — Flash Operation Error OPER. Cleared with system reset.
0x20038 SF_CLRE wo — HSM Clear Error Register resetvalue={Application Reset:0x0}
  [4] CEVER — Clear Erase Verify Error CEVER
  [3] CPVER — Clear Program Verify Error CPVER
  [1] CSQER — Clear Command Sequence Error CSQER
0x20040 SF_ECCR ro — HSM DF1 ECC Read Register resetvalue={Application Reset:0x0}
  fields as HF_ECCR
0x20044 SF_ECCS ro — HSM DF1 ECC Status Register resetvalue={Application Reset:0x0}
  [25] ABLANKA — Accumulated Blank Analog ABLANKA. The flag accumulates analog evaluated blank failures during NVM read accesses. It reports that all read data cells have sufficient high current a program of new data without prior erase is possible. Under certain operation history a valid complement data entry may also appear as blank. Data qualifiers like headers or footers which are usually used in EEPROM emulation can be used to distinguish expected valid data from unknown data fields. Only blank failures in Complement Sensing mode are reported in this flag and is intended for use only in this mode. Blank failures in Single Ended mode is also reported when in CFTM. Reset by hardware when DMU SF ECCC .CLR is written to 11 .
  [23] AERANY — Accumulated Any Read Access ECC Error AERANY. The status bit accumulates ECC failures during NVM read accesses. Reset by hardware when DMU SF ECCC .CLR is written to 11 .
  [19] AERM — Accumulated Multi bit ECC Errors AERM. The status bit accumulates multi bit failures during NVM read accesses. Reset by hardware when DMU SF ECCC .CLR is written to 11 .
  [18] AER3 — Accumulated Triple Bit ECC Errors AER3. The status flag accumulates triple bit failures during NVM read operations. Reset by hardware when DMU SF ECCC .CLR is written to 11 .
  [17] AER2 — Accumulated Double Bit ECC Errors AER2. The status flag accumulates double bit failures during NVM read operations. Reset by hardware when DMU SF ECCC .CLR is written to 11 .
  [16] AER1 — Accumulated Single Bit ECC Errors AER1. The status flag accumulates single bit failures during NVM read operations. Reset by hardware when DMU SF ECCC .CLR is written to 11 .
  [9] BLANKA — Read Access Blank Analog BLANKA. The flag reports that all read data cells have sufficient high current a program of new data without prior erase is possible. Under certain operation history a valid complement data entry may also appear as blank. Data qualifiers like headers or footers which are usually used in EEPROM emulation can be used to distinguish expected valid data from unknown data fields. Only blank failures in Complement Sensing mode are reported in this flag and is intended for use only in this mode. Blank failures in Single Ended mode is also reported when in CFTM. Reset by hardware when DMU SF ECCC .CLR is written to 11 .
  [7] ERRANY — Any Read Access ECC Error ERRANY. The flag reports any ECC failure during the last NVM read access. Reset by hardware when DMU SF ECCC .CLR is written to 11 .
  [3] ERRM — Read Access Multi bit ECC Error ERRM. The flag reports multi bit ECC failure during the last NVM read access. Reset by hardware when DMU SF ECCC .CLR is written to 11 .
  [2] ERR3 — Read Access Triple Bit ECC Error ERR3. The flag reports a triple bit ECC failure during the last NVM read access. Reset by hardware when DMU SF ECCC .CLR is written to 11 .
  [1] ERR2 — Read Access Double Bit ECC Error ERR2. The flag reports a double bit ECC failure during the last NVM read access. Reset by hardware when DMU SF ECCC .CLR is written to 11 .
  [0] ERR1 — Read Access Single Bit ECC Error ERR1. The flag reports a single bit ECC failure during the last NVM read access. Reset by hardware when DMU SF ECCC .CLR is written to 11 .
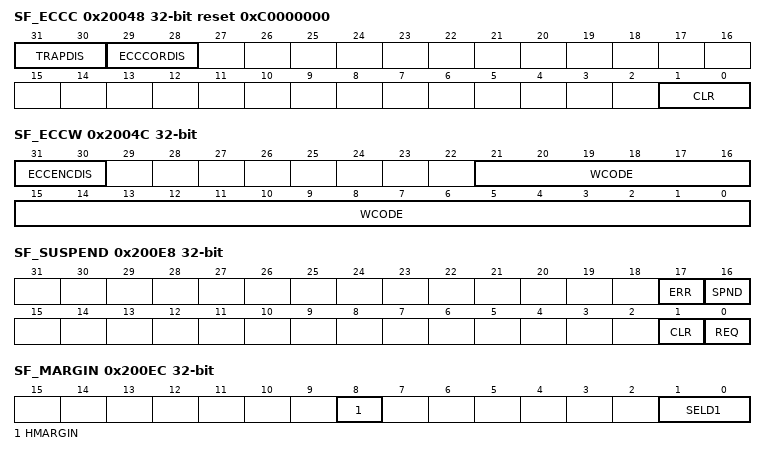
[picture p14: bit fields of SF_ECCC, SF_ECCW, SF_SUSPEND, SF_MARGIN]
0x20048 SF_ECCC access per field reset 0xC0000000 — HSM DF1 ECC Control Register resetvalue={Application Reset:0x0C0000000}
  [31:30] TRAPDIS rw — HSM Command Interface Uncorrectable ECC Bit Error Trap Disable TRAPDIS
  [29:28] ECCCORDIS rw — HSM Command Interface ECC Correction Disable ECCCORDIS
    0=Enabled0 (00 Enabled If DF1 is configured as HSM exclusive then ECC correction for the DF1 read path is enabled.); 1=Enabled1 (01 Enabled If DF1 is configured as HSM exclusive then ECC correction for the DF1 read path is enabled.); 2=Enabled2 (10 Enabled If DF1 is configured as HSM exclusive then ECC correction for the DF1 read path is enabled.); 3=Disabled3 (11 Disabled If DF1 is configured as HSM exclusive then ECC correction for the DF1 read path is disabled.)
  [1:0] CLR wo — Clear ECC status bits CLR
0x2004C SF_ECCW — HSM DF1 ECC Write Register resetvalue={Application Reset:0x0}
  [31:30] ECCENCDIS — ECC Encoding Disable ECCENCDIS
  [21:0] WCODE — Error Correction Write Code WCODE. 22 bit ECC code for the current 64 bit for DFLASH or 256 bit for PFLASH write buffer to be written into the assembly buffer instead of a generated ECC.
0x20074 SF_PROCONUSR ro — HSM DF1 User Mode Control resetvalue={Application Reset:0x0,CFS Value:0x0}
  [1:0] MODE — DF1 User Mode Control MODE. Configures the DF1 mode when the user has control.
0x200E8 SF_SUSPEND access per field — HSM Suspend Control Register resetvalue={Application Reset:0x0}
  [17] ERR ro — Suspend Error ERR. Reset by hardware when DMU SF SUSPEND .CLR is written to 1 .
  [16] SPND ro — Flash Operation Suspended SPND. Suspension of a Flash program or erase operation.
  [1] CLR wo — Suspend Clear CLR. Software write only active high clear of Suspend Error.
  [0] REQ rw — Suspend Request REQ
0x200EC SF_MARGIN — HSM DF1 Margin Control Register resetvalue={Application Reset:0x0}
  [8] HMARGIN — Hard Margin Selection HMARGIN. Suboptimal 0 bits are read as 1s. Suboptimal 1 bits are read as 0s. The concrete margin values are restored from the configuration sector and are determined by Infineon.
    values as HF_MARGIN.HMARGIN
  [1:0] SELD1 — DF1 Margin Read Selection SELD1. If a change between the standard and hard read margin setting is done the system must wait a delay time tFL MarginDel until the next read is requested.
0x30000 SP_PROCONHSMCFG ro — HSM Protection Configuration resetvalue={Application Reset:0x0,CFS Value:0x0}
  [13] BLKFLAN — Block Flash Analysis BLKFLAN. The commands x201c Verify Erased Page x201d x201c Verify Erased WL x201d x201c Verify Erased Logical Sector Range x201d are blocked on the HSM code ranges. Security functionally not part of the HSM. Also blocks User Margin Count User Vth Count and User Content Count .
  [12:11] DESTDBG — Destructive Debug Entry DESTDBG. This field configures the destructive debug entry. Security functionally not part of the HSM.
  [10:9] HSMENRES — Enable HSM Triggering Resets HSMENRES. This bit indicates whether HSM may trigger application or system resets.
  [8:7] HSMENPINS — Enable HSM Forcing of Pins HSM1 2 HSMENPINS. This bit indicates whether HSM may force the value of the pins HSM1 2 i.e. overrule the value driven by the application .
  [5:4] HSMRAMKEEP — HSM RAM Clear HSMRAMKEEP
  [2] HSMDX — HSM Data Sectors Exclusive HSMDX. This bit indicates whether the DFLASH1 logical sectors EEPROMx are configured as x201c HSM exclusive x201d .
  [1] SSWWAIT — SSW Wait SSWWAIT. Defines if the SSW waits for the HSM to release the jump of CPU0 to user code.
  [0] HSMBOOTEN — HSM Boot Enable HSMBOOTEN
0x30004 SP_PROCONHSMCBS ro — HSM Code Boot Sector resetvalue={Application Reset:0x0,CFS Value:0x0}
  [8n+5:8n] BOOTSEL{n} (n=0..3) — Boot Sector Selection BOOTSEL{n}. This field controls which of the HSM code sectors is searched for boot code. See CROSSREFERENCE .
0x30008 SP_PROCONHSMCX0 ro — HSM Code Exclusive Protection Configuration resetvalue={Application Reset:0x0,CFS Value:0x0}
  [n] HSM{n}X (n=0..31) — PFLASH Sector 31 HSM Code Exclusive HSM31X. This bit indicates whether the PFLASH logical sector is 8220 HSM exclusive 8221 .
0x3000C SP_PROCONHSMCX1 ro — HSM Code Exclusive Protection Configuration resetvalue={Application Reset:0x0,CFS Value:0x0}
  [n-32] HSM{n}X (n=32..39) — PFLASH Sector 39 HSM Code Exclusive HSM39X. This bit indicates whether the PFLASH logical sector is HSM exclusive .
0x30010 SP_PROCONHSMCOTP0 ro — HSM Code OTP Protection Configuration resetvalue={Application Reset:0x0,CFS Value:0x0}
  [n] HSM{n}ROM (n=0..31) — PFLASH Sector 31 HSM Code Locked Forever HSM31ROM. This bit indicates whether PFLASH sector is an HSM Code OTP protected sector with read only functionality.
0x30014 SP_PROCONHSMCOTP1 ro — HSM Code OTP Protection Configuration resetvalue={Application Reset:0x0,CFS Value:0x0}
  [n-32] HSM{n}ROM (n=32..39) — PFLASH Sector 39 HSM Code Locked Forever HSM39ROM. This bit indicates whether PFLASH sector is an HSM Code OTP protected sector with read only functionality.
0x30040 SP_PROCONHSM ro — HSM Interface Protection Configuration resetvalue={Application Reset:0x0,CFS Value:0x0}
  [6] HSMTRTYPE — HSM Type of Trace HSMTRTYPE. This bit field indicates which information can be captured by the BCU for HSM transactions. In order to ensure that with UCB delivery state HSM tracing is fully enabled the encoding for this bit field is inverted compared to the corresponding HSM control registers.
    0=TRDATA0 (0 TRDATA Trace addresses and data.); 1=TRADDR1 (1 TRADDR Trace addresses only.)
  [5:4] HSMTRDIS — HSM Trace Disable HSMTRDIS. This bit field indicates whether the HSM tracing and capturing of transactions for debug and in error cases via BCU is configured as 8220 disabled 8221 . In order to ensure that with UCB delivery state HSM tracing is fully enabled the encoding for this bit field is inverted compared to the corresponding HSM control registers.
    0=TRACEEN0 (00 TRACEEN Tracing enabled.); 1=TRACEDIS21 (01 TRACEDIS2 Tracing disabled.); 2=TRACEDIS12 (10 TRACEDIS1 Tracing disabled.); 3=TRACEDIS03 (11 TRACEDIS0 Tracing disabled.)
  [3] HSMTSTDIS — HSM Test Disable HSMTSTDIS. This bit indicates whether the HSM test is configured as 8220 disabled 8221 . HSMTSTDIS is not used.
  [2] TSTIFLCK — Test Interface Locked TSTIFLCK. This bit indicates whether the chip test interface is configured as locked . TSTIFLCK is not used.
  [1] DBGIFLCK — Debug Interface Locked DBGIFLCK. This bit indicates whether the chip debug interface is configured as 8220 locked 8221 .
  [0] HSMDBGDIS — HSM Debug Disable HSMDBGDIS. This bit indicates whether HSM debug is configured as 8220 disabled 8221 .
